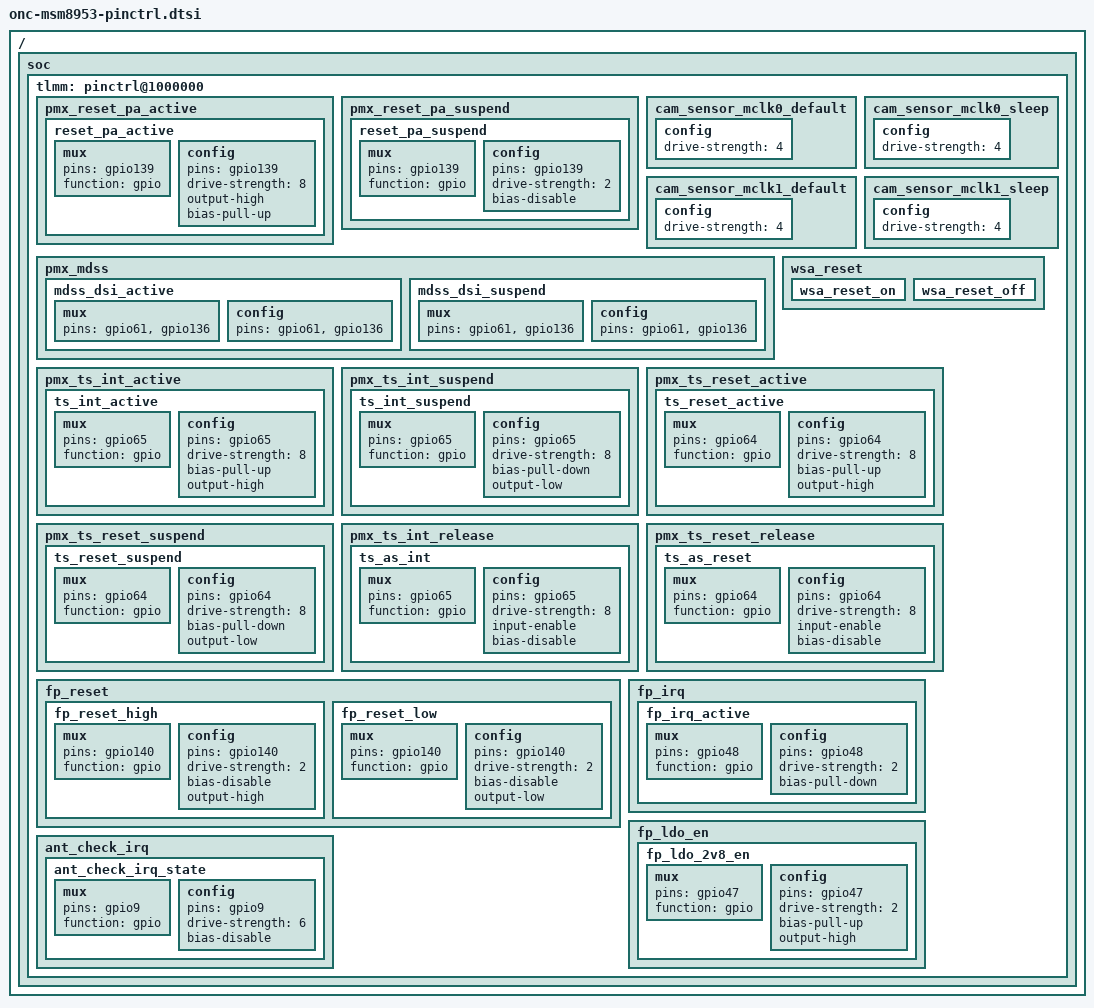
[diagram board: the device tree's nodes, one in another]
/*
 * Copyright (c) 2015-2019, The Linux Foundation. All rights reserved.
 * Copyright (C) 2020-2024 XiaoMi, Inc.
 *
 * This program is free software; you can redistribute it and/or modify
 * it under the terms of the GNU General Public License version 2 and
 * only version 2 as published by the Free Software Foundation.
 */

/ {
	soc {
		tlmm: pinctrl@1000000 {
			pmx_reset_pa_active {
				reset_pa_active: reset_pa_active {
					mux {
						pins = "gpio139";
						function = "gpio";
					};
					config {
						pins = "gpio139";
						drive-strength = <8>;
						output-high;
						bias-pull-up;
					};
				};
			};
			pmx_reset_pa_suspend {
				reset_pa_suspend: reset_pa_suspend {
					mux {
						pins = "gpio139";
						function = "gpio";
					};
					config {
						pins = "gpio139";
						drive-strength = <2>;
						bias-disable;
					};
				};
			};

			cam_sensor_mclk0_default: cam_sensor_mclk0_default {
				config {
					drive-strength = <4>;
				};
			};
			cam_sensor_mclk0_sleep: cam_sensor_mclk0_sleep {
				config {
					drive-strength = <4>;
				};
			};
			cam_sensor_mclk1_default: cam_sensor_mclk1_default {
				config {
					drive-strength = <4>;
				};
			};
			cam_sensor_mclk1_sleep: cam_sensor_mclk1_sleep {
				config {
					drive-strength = <4>;
				};
			};

			pmx_mdss {
				mdss_dsi_active: mdss_dsi_active {
					mux {
						pins = "gpio61", "gpio136";
					};
					config {
						pins = "gpio61", "gpio136";
					};
				};
				mdss_dsi_suspend: mdss_dsi_suspend {
					mux {
						pins = "gpio61", "gpio136";
					};
					config {
						pins = "gpio61", "gpio136";
					};
				};
			};

			wsa_reset {
				wsa_reset_on: wsa_reset_on {
					/delete-property/ pins;
				};
				wsa_reset_off: wsa_reset_off {
					/delete-property/ pins;
				};
			};

			pmx_ts_int_active {
				ts_int_active: ts_int_active {
					mux {
						pins = "gpio65";
						function = "gpio";
					};
					config {
						pins = "gpio65";
						drive-strength = <8>;
						bias-pull-up;
						output-high;
					};
				};
			};
			pmx_ts_int_suspend {
				ts_int_suspend: ts_int_suspend {
					mux {
						pins = "gpio65";
						function = "gpio";
					};
					config {
						pins = "gpio65";
						drive-strength = <8>;
						bias-pull-down;
						output-low;
					};
				};
			};
			pmx_ts_reset_active {
				ts_reset_active: ts_reset_active {
					mux {
						pins = "gpio64";
						function = "gpio";
					};
					config {
						pins = "gpio64";
						drive-strength = <8>;
						bias-pull-up;
						output-high;
					};
				};
			};
			pmx_ts_reset_suspend {
				ts_reset_suspend: ts_reset_suspend {
					mux {
						pins = "gpio64";
						function = "gpio";
					};
					config {
						pins = "gpio64";
						drive-strength = <8>;
						bias-pull-down;
						output-low;
					};
				};
			};
			pmx_ts_int_release {
				ts_as_int: ts_as_int {
					mux {
						pins = "gpio65";
						function = "gpio";
					};
					config {
						pins = "gpio65";
						drive-strength = <8>;
						input-enable;
						bias-disable;
					};
				};
			};
			pmx_ts_reset_release {
				ts_as_reset: ts_as_reset {
					mux {
						pins = "gpio64";
						function = "gpio";
					};
					config {
						pins = "gpio64";
						drive-strength = <8>;
						input-enable;
						bias-disable;
					};
				};
			};

			fp_reset {
				fp_reset_high:fp_reset_high {
					mux {
						pins = "gpio140";
						function = "gpio";
					};
					config {
						pins = "gpio140";
						drive-strength = <2>;
						bias-disable;
						output-high;
					};
				};
				fp_reset_low:fp_reset_low {
					mux {
						pins = "gpio140";
						function = "gpio";
					};
					config {
						pins = "gpio140";
						drive-strength = <2>;
						bias-disable;
						output-low;
					};
				};
			};
			fp_irq {
				fp_irq_active:fp_irq_active {
					mux {
						pins = "gpio48";
						function = "gpio";
					};
					config {
						pins = "gpio48";
						drive-strength = <2>;
						bias-pull-down;
					};
				};
			};
			fp_ldo_en {
				fp_ldo_2v8_en:fp_ldo_2v8_en {
					mux {
						pins = "gpio47";
						function = "gpio";
					};
					config {
						pins = "gpio47";
						drive-strength = <2>;
						bias-pull-up;
						output-high;
					};
				};
			};

			ant_check_irq {
				ant_check_irq_state: ant_check_irq_state {
					mux {
						pins = "gpio9";
						function = "gpio";
					};
					config {
						pins = "gpio9";
						drive-strength = <6>;
						bias-disable;
					};
				};
			};
			/* Delete node commented out by OEM */
			/delete-node/ typec_ssmux_config;
		};
	};
};
